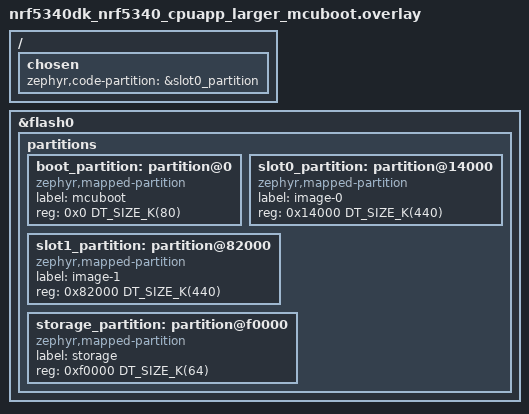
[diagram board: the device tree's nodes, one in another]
/*
 * Copyright (c) 2026 Nordic Semiconductor ASA
 *
 * SPDX-License-Identifier: LicenseRef-Nordic-5-Clause
 */

&flash0 {
	/delete-node/ partitions;

	partitions {
		ranges;
		#address-cells = <1>;
		#size-cells = <1>;

		boot_partition: partition@0 {
			compatible = "zephyr,mapped-partition";
			label = "mcuboot";
			reg = <0x0 DT_SIZE_K(80)>;
		};

		slot0_partition: partition@14000 {
			compatible = "zephyr,mapped-partition";
			label = "image-0";
			reg = <0x14000 DT_SIZE_K(440)>;
		};

		slot1_partition: partition@82000 {
			compatible = "zephyr,mapped-partition";
			label = "image-1";
			reg = <0x82000 DT_SIZE_K(440)>;
		};

		storage_partition: partition@f0000 {
			compatible = "zephyr,mapped-partition";
			label = "storage";
			reg = <0xf0000 DT_SIZE_K(64)>;
		};
	};
};

/ {
	chosen {
		zephyr,code-partition = &slot0_partition;
	};
};
